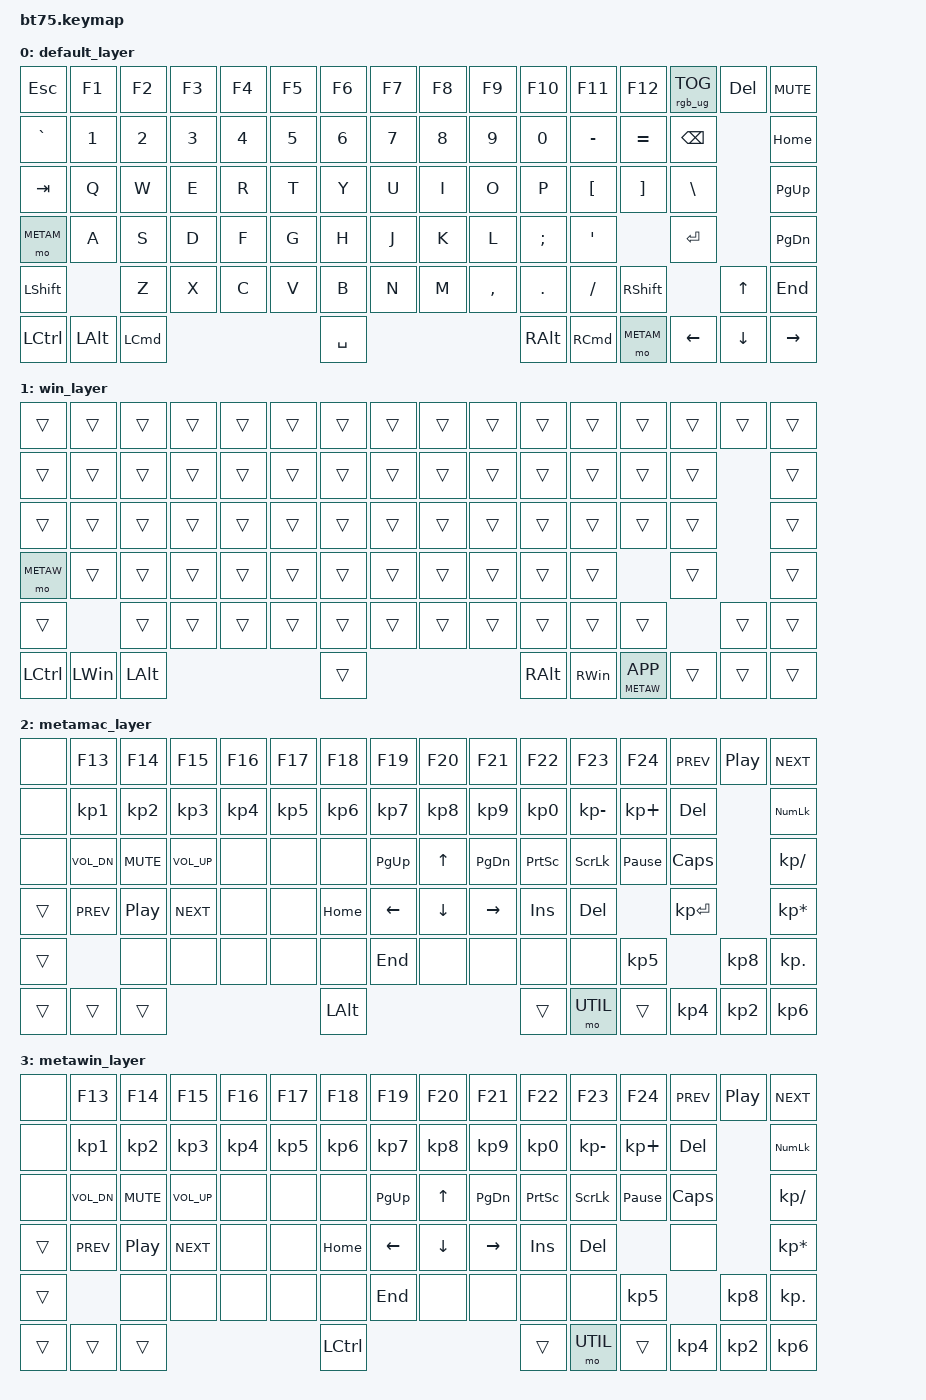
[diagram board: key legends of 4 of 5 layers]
#include <behaviors.dtsi>
#include <dt-bindings/zmk/keys.h>
#include <dt-bindings/zmk/bt.h>
#include <dt-bindings/zmk/rgb.h>
#include <dt-bindings/zmk/backlight.h>
#include <dt-bindings/zmk/ext_power.h>
#include <dt-bindings/zmk/outputs.h>

#define DEFAULT 0
#define WIN 1
#define METAM 2
#define METAW 3
#define UTIL 4

/ {
    keymap {
        compatible = "zmk,keymap";
        default_layer {
                // Regular macOS bottom row on the left, custom on the right; switches to metamac layer
                // ------------------------------------------------------------------------------------------------
				// | ESC | F1  | F2  | F3  | F4  | F5  | F6  | F7  | F9  | F9  | F10 | F11 | F12 | RGB | DEL| MUTE|
                // |  `  |  1  |  2  |  3  |  4  |  5  |  6  |  7  |  8  |  9  |  0  |  -  |  =  |   BKSP   | HOME|
                // |  TAB |  Q  |  W  |  E  |  R  |  T  |  Y  |  U  |  I  |  O  |  P  |  [  |  ]  |   \     | PGUP|
                // |  LAY   |  A  |  S  |  D  |  F  |  G  |  H  |  J  |  K  |  L  |  ;  |  '  |    ENTER    | PGDN|
                // |  SHIFT  |  Z  |  X  |  C  |  V  |  B  |  N  |  M  |  ,  |  .  | /   |  SHIFT     | UP  | END |
                // |  CTL  |  OPT  |  CMD  |             SPACE              | ALT | CMD | LAY |  LEFT | DOWN|RIGHT|
                // ------------------------------------------------------------------------------------------------
            bindings = <
				&kp ESC			&kp F1			&kp F2			&kp F3			&kp F4			&kp F5			&kp F6			&kp F7			&kp F8			&kp F9			&kp F10			&kp F11			&kp F12			&rgb_ug RGB_TOG	&kp DEL		    &kp C_MUTE
                &kp GRAVE 		&kp N1 			&kp N2 			&kp N3 			&kp N4 			&kp N5 			&kp N6 			&kp N7 			&kp N8 			&kp N9 			&kp N0 			&kp MINUS 		&kp EQUAL 		&kp BSPC		    			&kp HOME
                &kp TAB 		&kp Q 			&kp W 			&kp E 			&kp R 			&kp T 			&kp Y 			&kp U 			&kp I 			&kp O 			&kp P 			&kp LBKT 		&kp RBKT 		&kp BSLH						&kp PG_UP
                &mo METAM 		&kp A 			&kp S 			&kp D 			&kp F 			&kp G 			&kp H 			&kp J 			&kp K 			&kp L 			&kp SEMI 		&kp SQT 						&kp RET							&kp PG_DN
                &kp LSHFT 						&kp Z 			&kp X 			&kp C 			&kp V 			&kp B 			&kp N 			&kp M 			&kp COMMA 		&kp DOT 		&kp FSLH 		&kp RSHFT						&kp UP			&kp END
                &kp LCTRL 		&kp LALT 		&kp LCMD														&kp SPACE 														&kp RALT 		&kp RCMD 		&mo METAM 		&kp LEFT		&kp DOWN		&kp RIGHT
            >;
            sensor-bindings = <&inc_dec_kp LS(LA(C_VOL_UP)) LS(LA(C_VOL_DN))>;
        };
        win_layer {
                // Regular IBM/Windows bottom row; switches to metawin layer
				 // ------------------------------------------------------------------------------------------------
				// | ESC | F1  | F2  | F3  | F4  | F5  | F6  | F7  | F9  | F9  | F10 | F11 | F12 | RGB | DEL| MUTE|
                // |  `  |  1  |  2  |  3  |  4  |  5  |  6  |  7  |  8  |  9  |  0  |  -  |  =  |   BKSP   | HOME|
                // |  TAB |  Q  |  W  |  E  |  R  |  T  |  Y  |  U  |  I  |  O  |  P  |  [  |  ]  |   \     | PGUP|
                // |  LAY   |  A  |  S  |  D  |  F  |  G  |  H  |  J  |  K  |  L  |  ;  |  '  |    ENTER    | PGDN|
                // |  SHIFT  |  Z  |  X  |  C  |  V  |  B  |  N  |  M  |  ,  |  .  | /   |  SHIFT     | UP  | END |
                // |  CTL  |  WIN  |  ALT  |             SPACE              | ALT | WIN | LAY |  LEFT | DOWN|RIGHT|
                // ------------------------------------------------------------------------------------------------
            bindings = <
                &trans 			&trans 			&trans 			&trans 			&trans 			&trans 			&trans 			&trans 			&trans 			&trans 			&trans 			&trans 			&trans			&trans 			&trans 			&trans
				&trans 			&trans 			&trans 			&trans 			&trans 			&trans 			&trans 			&trans 			&trans 			&trans 			&trans 			&trans 			&trans 			&trans 			     			&trans
                &trans 			&trans 			&trans 			&trans 			&trans 			&trans 			&trans 			&trans 			&trans 			&trans 			&trans 			&trans 			&trans 			&trans							&trans
                &mo METAW 		&trans 			&trans 			&trans 			&trans 			&trans 			&trans 			&trans 			&trans 			&trans 			&trans 			&trans 							&trans							&trans
                &trans 							&trans 			&trans 			&trans 			&trans 			&trans 			&trans 			&trans 			&trans 			&trans 			&trans 			&trans							&trans			&trans
                &kp LCTRL 		&kp LWIN 		&kp LALT 														&trans 															&kp RALT 		&kp RWIN 		&lt METAW K_APP &trans			&trans			&trans
            >;
            sensor-bindings = <&inc_dec_kp C_VOL_UP C_VOL_DN>;
        };
        metamac_layer {
                // F-keys, navigation, media controls, syskeys, Alt on Space
            bindings = <
                &none 			&kp F13			&kp F14			&kp F15			&kp F16			&kp F17			&kp F18			&kp F19			&kp F20			&kp F21			&kp F22			&kp F23			&kp F24			&kp C_PREV 		&kp C_PP 		&kp C_NEXT
				&none	 		&kp KP_N1 		&kp KP_N2 		&kp KP_N3 		&kp KP_N4 		&kp KP_N5 		&kp KP_N6 		&kp KP_N7 		&kp KP_N8 		&kp KP_N9 		&kp KP_N0 		&kp KP_MINUS 	&kp KP_PLUS 	&kp DEL 		     			&kp KP_NUM
                &none 			&kp C_VOL_DN 	&kp K_MUTE 		&kp C_VOL_UP 	&none 			&none 			&none 			&kp PG_UP 		&kp UP 			&kp PG_DN 		&kp PSCRN 		&kp SLCK 		&kp PAUSE_BREAK &kp CAPS						&kp KP_DIVIDE
                &trans 			&kp C_PREV 		&kp C_PP 		&kp C_NEXT 		&none 			&none 			&kp HOME 		&kp LEFT 		&kp DOWN 		&kp RIGHT 		&kp INS 		&kp DEL 						&kp KP_ENTER					&kp KP_MULTIPLY
                &trans 							&none 			&none 			&none 			&none 			&none 			&kp END 		&none 			&none 			&none 			&none 			&kp KP_N5						&kp KP_N8		&kp KP_DOT
                &trans 			&trans 			&trans 															&kp LALT 														&trans 			&mo UTIL 		&trans 			&kp KP_N4		&kp KP_N2		&kp KP_N6
            >;
            sensor-bindings = <&inc_dec_kp C_NEXT C_PREV>;
        };
        metawin_layer {
                // F-keys, navigation, media controls, syskeys, Ctrl on Space
            bindings = <
				&none 			&kp F13			&kp F14			&kp F15			&kp F16			&kp F17			&kp F18			&kp F19			&kp F20			&kp F21			&kp F22			&kp F23			&kp F24			&kp C_PREV 		&kp C_PP 		&kp C_NEXT
                &none	 		&kp KP_N1 		&kp KP_N2 		&kp KP_N3 		&kp KP_N4 		&kp KP_N5 		&kp KP_N6 		&kp KP_N7 		&kp KP_N8 		&kp KP_N9 		&kp KP_N0 		&kp KP_MINUS 	&kp KP_PLUS 	&kp DEL			    			&kp KP_NUM
                &none 			&kp C_VOL_DN 	&kp K_MUTE 		&kp C_VOL_UP 	&none 			&none 			&none 			&kp PG_UP 		&kp UP 			&kp PG_DN 		&kp PSCRN 		&kp SLCK 		&kp PAUSE_BREAK &kp CAPS						&kp KP_DIVIDE
                &trans 			&kp C_PREV 		&kp C_PP 		&kp C_NEXT 		&none 			&none 			&kp HOME 		&kp LEFT 		&kp DOWN 		&kp RIGHT 		&kp INS 		&kp DEL 						&none							&kp KP_MULTIPLY
                &trans 							&none 			&none 			&none 			&none 			&none 			&kp END 		&none 			&none 			&none 			&none 			&kp KP_N5						&kp KP_N8		&kp KP_DOT
                &trans 			&trans 			&trans 															&kp LCTRL 														&trans 			&mo UTIL 		&trans 			&kp KP_N4		&kp KP_N2		&kp KP_N6
            >;
            sensor-bindings = <&inc_dec_kp C_NEXT C_PREV>;
        };
        util_layer {
                // Hardware functions, layer toggles
            bindings = <
				&none 			&none 			&none 			&none 			&none 			&none 			&none	        &none	        &none	        &none	        &none	        &none	        &none	        &rgb_ug RGB_SPD	&rgb_ug RGB_SPI	&rgb_ug RGB_HUI
                &none 			&bt BT_SEL 0 	&bt BT_SEL 1 	&bt BT_SEL 2 	&bt BT_SEL 3 	&bt BT_SEL 4 	&none 			&none 			&none 			&none 			&bl BL_TOG 		&bl BL_DEC 		&bl BL_INC 		&sys_reset			    			&rgb_ug RGB_HUD
                &none 			&none 			&tog WIN 		&none 			&none 			&none 			&none 			&out OUT_USB 	&none 			&none           &none           &none 		    &none 			&none							&rgb_ug RGB_SAI
                &trans 			&none 			&none 			&none 			&none 			&none 			&none 			&none 			&none 			&none 			&none 			&none 							&bootloader						&rgb_ug RGB_SAD
                &none 							&none 			&none 			&bt BT_CLR 		&none 			&out OUT_BLE 	&none 			&none 			&none 			&none 			&none 			&rgb_ug RGB_COLOR_HSB(29,27,100)&rgb_ug RGB_BRI	&rgb_ug RGB_TOG
                &none 			&none 			&none 															&kp K_PWR 														&none 			&trans	 		&trans 			&rgb_ug RGB_EFR	&rgb_ug RGB_BRD	&rgb_ug RGB_EFF
            >;
            sensor-bindings = <&inc_dec_kp C_VOL_UP C_VOL_DN>;
        };
    };
};
